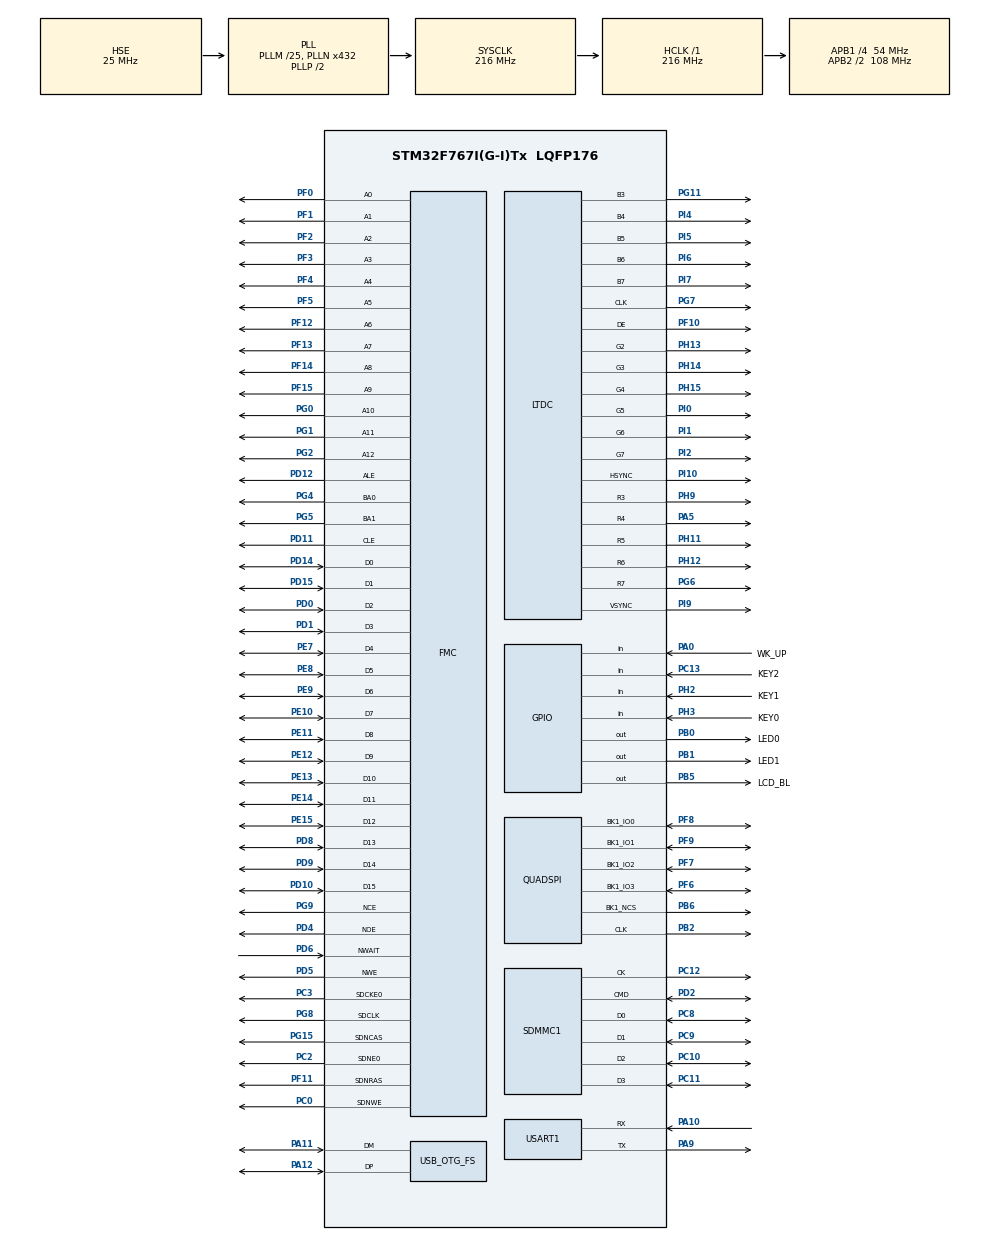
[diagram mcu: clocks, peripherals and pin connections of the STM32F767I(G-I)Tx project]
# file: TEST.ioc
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CORTEX_M7.ART_ACCLERATOR_ENABLE=1
CORTEX_M7.CPU_DCache=Enabled
CORTEX_M7.CPU_ICache=Enabled
CORTEX_M7.PREFETCH_ENABLE=1
Dma.Request0=USART1_RX
Dma.Request1=USART1_TX
Dma.USART1_RX.0.Direction=DMA_PERIPH_TO_MEMORY
Dma.USART1_RX.0.FIFOMode=DMA_FIFOMODE_DISABLE
Dma.USART1_RX.0.Instance=DMA2_Stream2
Dma.USART1_RX.0.MemDataAlignment=DMA_MDATAALIGN_BYTE
Dma.USART1_RX.0.MemInc=DMA_MINC_ENABLE
Dma.USART1_RX.0.Mode=DMA_NORMAL
Dma.USART1_RX.0.PeriphDataAlignment=DMA_PDATAALIGN_BYTE
Dma.USART1_RX.0.PeriphInc=DMA_PINC_DISABLE
Dma.USART1_RX.0.Priority=DMA_PRIORITY_LOW
Dma.USART1_TX.1.Direction=DMA_MEMORY_TO_PERIPH
Dma.USART1_TX.1.FIFOMode=DMA_FIFOMODE_DISABLE
Dma.USART1_TX.1.Instance=DMA2_Stream7
Dma.USART1_TX.1.MemDataAlignment=DMA_MDATAALIGN_BYTE
Dma.USART1_TX.1.MemInc=DMA_MINC_ENABLE
Dma.USART1_TX.1.Mode=DMA_NORMAL
Dma.USART1_TX.1.PeriphDataAlignment=DMA_PDATAALIGN_BYTE
Dma.USART1_TX.1.PeriphInc=DMA_PINC_DISABLE
Dma.USART1_TX.1.Priority=DMA_PRIORITY_LOW
FMC.AttributeSpaceHiZSetupTime1=2
FMC.AttributeSpaceHoldSetupTime1=3
FMC.AttributeSpaceSetupTime1=2
FMC.AttributeSpaceWaitSetupTime1=3
FMC.CASLatency1=FMC_SDRAM_CAS_LATENCY_3
FMC.ColumnBitsNumber1=FMC_SDRAM_COLUMN_BITS_NUM_9
FMC.CommonSpaceHiZSetupTime1=2
FMC.CommonSpaceHoldSetupTime1=3
FMC.CommonSpaceSetupTime1=2
FMC.CommonSpaceWaitSetupTime1=3
FMC.ECCPageSize1=FMC_NAND_ECC_PAGE_SIZE_512BYTE
FMC.EccComputation1=FMC_NAND_ECC_DISABLE
FMC.ExitSelfRefreshDelay1=8
FMC.LoadToActiveDelay1=2
FMC.NandBlockNbr1=4096
FMC.NandBlockSize1=64
FMC.NandPageSize1=2046
FMC.NandPlaneNbr1=2
FMC.NandPlaneSize1=2048
FMC.NandSpareAreaSize1=64
FMC.RCDDelay1=2
FMC.RPDelay1=2
FMC.ReadBurst1=FMC_SDRAM_RBURST_ENABLE
FMC.ReadPipeDelay1=FMC_SDRAM_RPIPE_DELAY_1
FMC.RowCycleDelay1=6
FMC.SDClockPeriod1=FMC_SDRAM_CLOCK_PERIOD_2
FMC.SelfRefreshTime1=6
FMC.WriteRecoveryTime1=4
LTDC.ActiveH=272
LTDC.ActiveW=480
LTDC.Alpha_L0=0xff
LTDC.Alpha_L1=0x7f
LTDC.BlendingFactor1_L0=LTDC_BLENDING_FACTOR1_CA
LTDC.BlendingFactor1_L1=LTDC_BLENDING_FACTOR1_PAxCA
LTDC.BlendingFactor2_L0=LTDC_BLENDING_FACTOR2_CA
LTDC.BlendingFactor2_L1=LTDC_BLENDING_FACTOR2_PAxCA
LTDC.FBStartAdress_L0=0xC0000000  
LTDC.FBStartAdress_L1=0xc00fa000
LTDC.HBP=40
LTDC.HFP=5
LTDC.HSync=1
LTDC.ImageHeight_L0=272
LTDC.ImageHeight_L1=272
LTDC.ImageWidth_L0=480
LTDC.ImageWidth_L1=480
LTDC.Layers=0
LTDC.PixelFormat_L0=LTDC_PIXEL_FORMAT_RGB565
LTDC.PixelFormat_L1=LTDC_PIXEL_FORMAT_RGB565
LTDC.VBP=8
LTDC.VFP=8
LTDC.VSync=1
LTDC.WindowX1_L0=480
LTDC.WindowX1_L1=480
LTDC.WindowY1_L0=272
LTDC.WindowY1_L1=272
Mcu.Family=STM32F7
Mcu.Name=STM32F767I(G-I)Tx
Mcu.Package=LQFP176
NVIC.DMA2_Stream2_IRQn=true\:0\:0\:true\:false\:true\:false\:true
NVIC.DMA2_Stream7_IRQn=true\:0\:0\:false\:false\:true\:false\:true
NVIC.OTG_FS_IRQn=true\:3\:0\:true\:false\:true\:true\:true
NVIC.PriorityGroup=NVIC_PRIORITYGROUP_4
NVIC.TIM3_IRQn=true\:0\:0\:false\:false\:true\:true\:true
NVIC.USART1_IRQn=true\:0\:0\:false\:false\:true\:true\:true
PA0/WKUP.GPIO_Label=WK_UP
PA0/WKUP.GPIO_PuPd=GPIO_PULLDOWN
PA0/WKUP.Signal=GPIO_Input
PA10.Mode=Asynchronous
PA10.Signal=USART1_RX
PA11.Mode=Device_Only
PA11.Signal=USB_OTG_FS_DM
PA12.Mode=Device_Only
PA12.Signal=USB_OTG_FS_DP
PA13.Mode=Serial_Wire
PA13.Signal=SYS_JTMS-SWDIO
PA14.Mode=Serial_Wire
PA14.Signal=SYS_JTCK-SWCLK
PA5.GPIO_Speed=GPIO_SPEED_FREQ_VERY_HIGH
PA5.Mode=RGB565
PA5.Signal=LTDC_R4
PA9.Mode=Asynchronous
PA9.Signal=USART1_TX
PB0.GPIO_Label=LED0
PB0.GPIO_Speed=GPIO_SPEED_FREQ_VERY_HIGH
PB0.Signal=GPIO_Output
PB1.GPIO_Label=LED1
PB1.Signal=GPIO_Output
PB2.Mode=Single Bank 1
PB2.Signal=QUADSPI_CLK
PB5.GPIO_Label=LCD_BL
PB5.GPIO_PuPd=GPIO_PULLUP
PB5.GPIO_Speed=GPIO_SPEED_FREQ_VERY_HIGH
PB5.PinState=GPIO_PIN_SET
PB5.Signal=GPIO_Output
PB6.Mode=Single Bank 1
PB6.Signal=QUADSPI_BK1_NCS
PC0.Signal=FMC_SDNWE
PC10.GPIO_PuPd=GPIO_PULLUP
PC10.Mode=SD_4_bits_Wide_bus
PC10.Signal=SDMMC1_D2
PC11.GPIO_PuPd=GPIO_PULLUP
PC11.Mode=SD_4_bits_Wide_bus
PC11.Signal=SDMMC1_D3
PC12.GPIO_PuPd=GPIO_PULLUP
PC12.Mode=SD_4_bits_Wide_bus
PC12.Signal=SDMMC1_CK
PC13.GPIO_Label=KEY2
PC13.GPIO_PuPd=GPIO_PULLUP
PC13.Signal=GPIO_Input
PC2.Mode=SdramChipSelect1_1
PC2.Signal=FMC_SDNE0
PC3.Mode=SdramChipSelect1_1
PC3.Signal=FMC_SDCKE0
PC8.GPIO_PuPd=GPIO_PULLUP
PC8.Mode=SD_4_bits_Wide_bus
PC8.Signal=SDMMC1_D0
PC9.GPIO_PuPd=GPIO_PULLUP
PC9.Mode=SD_4_bits_Wide_bus
PC9.Signal=SDMMC1_D1
PD0.Signal=FMC_D2_DA2
PD1.Signal=FMC_D3_DA3
PD10.Signal=FMC_D15_DA15
PD11.Signal=FMC_A16_CLE
PD12.Signal=FMC_A17_ALE
PD14.Signal=FMC_D0_DA0
PD15.Signal=FMC_D1_DA1
PD2.GPIO_PuPd=GPIO_PULLUP
PD2.Mode=SD_4_bits_Wide_bus
PD2.Signal=SDMMC1_CMD
PD4.Signal=FMC_NOE
PD5.Signal=FMC_NWE
PD6.Signal=FMC_NWAIT
PD8.Signal=FMC_D13_DA13
PD9.Signal=FMC_D14_DA14
PE10.Signal=FMC_D7_DA7
PE11.Signal=FMC_D8_DA8
PE12.Signal=FMC_D9_DA9
PE13.Signal=FMC_D10_DA10
PE14.Signal=FMC_D11_DA11
PE15.Signal=FMC_D12_DA12
PE7.Signal=FMC_D4_DA4
PE8.Signal=FMC_D5_DA5
PE9.Signal=FMC_D6_DA6
PF0.Signal=FMC_A0
PF1.Signal=FMC_A1
PF10.GPIO_Speed=GPIO_SPEED_FREQ_VERY_HIGH
PF10.Mode=RGB565
PF10.Signal=LTDC_DE
PF11.Signal=FMC_SDNRAS
PF12.Signal=FMC_A6
PF13.Signal=FMC_A7
PF14.Signal=FMC_A8
PF15.Signal=FMC_A9
PF2.Signal=FMC_A2
PF3.Signal=FMC_A3
PF4.Signal=FMC_A4
PF5.Signal=FMC_A5
PF6.Mode=Single Bank 1
PF6.Signal=QUADSPI_BK1_IO3
PF7.Mode=Single Bank 1
PF7.Signal=QUADSPI_BK1_IO2
PF8.Mode=Single Bank 1
PF8.Signal=QUADSPI_BK1_IO0
PF9.Mode=Single Bank 1
PF9.Signal=QUADSPI_BK1_IO1
PG0.Signal=FMC_A10
PG1.Signal=FMC_A11
PG11.GPIO_Speed=GPIO_SPEED_FREQ_VERY_HIGH
PG11.Mode=RGB565
PG11.Signal=LTDC_B3
PG15.Signal=FMC_SDNCAS
PG2.Signal=FMC_A12
PG4.Signal=FMC_A14_BA0
PG5.Signal=FMC_A15_BA1
PG6.GPIO_Speed=GPIO_SPEED_FREQ_VERY_HIGH
PG6.Mode=RGB565
PG6.Signal=LTDC_R7
PG7.GPIO_Speed=GPIO_SPEED_FREQ_VERY_HIGH
PG7.Mode=RGB565
PG7.Signal=LTDC_CLK
PG8.Signal=FMC_SDCLK
PG9.Mode=NandChipSelect3_1
PG9.Signal=FMC_NCE
PH0/OSC_IN.Mode=HSE-External-Oscillator
PH0/OSC_IN.Signal=RCC_OSC_IN
PH1/OSC_OUT.Mode=HSE-External-Oscillator
PH1/OSC_OUT.Signal=RCC_OSC_OUT
PH11.GPIO_Speed=GPIO_SPEED_FREQ_VERY_HIGH
PH11.Mode=RGB565
PH11.Signal=LTDC_R5
PH12.GPIO_Speed=GPIO_SPEED_FREQ_VERY_HIGH
PH12.Mode=RGB565
PH12.Signal=LTDC_R6
PH13.GPIO_Speed=GPIO_SPEED_FREQ_VERY_HIGH
PH13.Mode=RGB565
PH13.Signal=LTDC_G2
PH14.GPIO_Speed=GPIO_SPEED_FREQ_VERY_HIGH
PH14.Mode=RGB565
PH14.Signal=LTDC_G3
PH15.GPIO_Speed=GPIO_SPEED_FREQ_VERY_HIGH
PH15.Mode=RGB565
PH15.Signal=LTDC_G4
PH2.GPIO_Label=KEY1
PH2.GPIO_PuPd=GPIO_PULLUP
PH2.Signal=GPIO_Input
PH3.GPIO_Label=KEY0
PH3.GPIO_PuPd=GPIO_PULLUP
PH3.Signal=GPIO_Input
PH9.GPIO_Speed=GPIO_SPEED_FREQ_VERY_HIGH
PH9.Mode=RGB565
PH9.Signal=LTDC_R3
PI0.GPIO_Speed=GPIO_SPEED_FREQ_VERY_HIGH
PI0.Mode=RGB565
PI0.Signal=LTDC_G5
PI1.GPIO_Speed=GPIO_SPEED_FREQ_VERY_HIGH
PI1.Mode=RGB565
PI1.Signal=LTDC_G6
PI10.GPIO_Speed=GPIO_SPEED_FREQ_VERY_HIGH
PI10.Mode=RGB565
PI10.Signal=LTDC_HSYNC
PI2.GPIO_Speed=GPIO_SPEED_FREQ_VERY_HIGH
PI2.Mode=RGB565
PI2.Signal=LTDC_G7
PI4.GPIO_Speed=GPIO_SPEED_FREQ_VERY_HIGH
PI4.Mode=RGB565
PI4.Signal=LTDC_B4
PI5.GPIO_Speed=GPIO_SPEED_FREQ_VERY_HIGH
PI5.Mode=RGB565
PI5.Signal=LTDC_B5
PI6.GPIO_Speed=GPIO_SPEED_FREQ_VERY_HIGH
PI6.Mode=RGB565
PI6.Signal=LTDC_B6
PI7.GPIO_Speed=GPIO_SPEED_FREQ_VERY_HIGH
PI7.Mode=RGB565
PI7.Signal=LTDC_B7
PI9.GPIO_Speed=GPIO_SPEED_FREQ_VERY_HIGH
PI9.Mode=RGB565
PI9.Signal=LTDC_VSYNC
ProjectManager.HeapSize=0x200
ProjectManager.StackSize=0x800
ProjectManager.TargetToolchain=MDK-ARM V5
QUADSPI.ChipSelectHighTime=QSPI_CS_HIGH_TIME_4_CYCLE
QUADSPI.ClockPrescaler=2
QUADSPI.FifoThreshold=4
QUADSPI.FlashSize=24
QUADSPI.SampleShifting=QSPI_SAMPLE_SHIFTING_HALFCYCLE
RCC.AHBFreq_Value=216000000
RCC.APB1CLKDivider=RCC_HCLK_DIV4
RCC.APB1Freq_Value=54000000
RCC.APB1TimFreq_Value=108000000
RCC.APB2CLKDivider=RCC_HCLK_DIV2
RCC.APB2Freq_Value=108000000
RCC.APB2TimFreq_Value=216000000
RCC.CortexFreq_Value=216000000
RCC.HCLKFreq_Value=216000000
RCC.HSE_VALUE=25000000
RCC.HSI_VALUE=16000000
RCC.LSE_VALUE=32768
RCC.PLLM=25
RCC.PLLN=432
RCC.PLLQ=9
RCC.PLLSAIN=432
RCC.PLLSAIR=6
RCC.PLLSAIRDiv=RCC_PLLSAIDIVR_8
RCC.SDMMCClockSelection=RCC_SDMMC1CLKSOURCE_CLK48
RCC.SYSCLKFreq_VALUE=216000000
RCC.SYSCLKSource=RCC_SYSCLKSOURCE_PLLCLK
RCC.USBFreq_Value=48000000
RCC.VCOOutputFreq_Value=432000000
SH.FMC_A0.0=FMC_A0,13b-sda1
SH.FMC_A1.0=FMC_A1,13b-sda1
SH.FMC_A10.0=FMC_A10,13b-sda1
SH.FMC_A11.0=FMC_A11,13b-sda1
SH.FMC_A12.0=FMC_A12,13b-sda1
SH.FMC_A14_BA0.0=FMC_BA0,FourSdramBanks1
SH.FMC_A15_BA1.0=FMC_BA1,FourSdramBanks1
SH.FMC_A16_CLE.0=FMC_CLE,8b-dmux1
SH.FMC_A17_ALE.0=FMC_ALE,8b-dmux1
SH.FMC_A2.0=FMC_A2,13b-sda1
SH.FMC_A3.0=FMC_A3,13b-sda1
SH.FMC_A4.0=FMC_A4,13b-sda1
SH.FMC_A5.0=FMC_A5,13b-sda1
SH.FMC_A6.0=FMC_A6,13b-sda1
SH.FMC_A7.0=FMC_A7,13b-sda1
SH.FMC_A8.0=FMC_A8,13b-sda1
SH.FMC_A9.0=FMC_A9,13b-sda1
SH.FMC_D0_DA0.0=FMC_D0,sd-16b-d1
SH.FMC_D0_DA0.1=FMC_D0,8b-dmux1
SH.FMC_D10_DA10.0=FMC_D10,sd-16b-d1
SH.FMC_D11_DA11.0=FMC_D11,sd-16b-d1
SH.FMC_D12_DA12.0=FMC_D12,sd-16b-d1
SH.FMC_D13_DA13.0=FMC_D13,sd-16b-d1
SH.FMC_D14_DA14.0=FMC_D14,sd-16b-d1
SH.FMC_D15_DA15.0=FMC_D15,sd-16b-d1
SH.FMC_D1_DA1.0=FMC_D1,sd-16b-d1
SH.FMC_D1_DA1.1=FMC_D1,8b-dmux1
SH.FMC_D2_DA2.0=FMC_D2,sd-16b-d1
SH.FMC_D2_DA2.1=FMC_D2,8b-dmux1
SH.FMC_D3_DA3.0=FMC_D3,sd-16b-d1
SH.FMC_D3_DA3.1=FMC_D3,8b-dmux1
SH.FMC_D4_DA4.0=FMC_D4,sd-16b-d1
SH.FMC_D4_DA4.1=FMC_D4,8b-dmux1
SH.FMC_D5_DA5.0=FMC_D5,sd-16b-d1
SH.FMC_D5_DA5.1=FMC_D5,8b-dmux1
SH.FMC_D6_DA6.0=FMC_D6,sd-16b-d1
SH.FMC_D6_DA6.1=FMC_D6,8b-dmux1
SH.FMC_D7_DA7.0=FMC_D7,sd-16b-d1
SH.FMC_D7_DA7.1=FMC_D7,8b-dmux1
SH.FMC_D8_DA8.0=FMC_D8,sd-16b-d1
SH.FMC_D9_DA9.0=FMC_D9,sd-16b-d1
SH.FMC_NOE.0=FMC_NOE,8b-dmux1
SH.FMC_NWAIT.0=FMC_NWAIT,Wait1
SH.FMC_NWE.0=FMC_NWE,8b-dmux1
SH.FMC_SDCLK.0=FMC_SDCLK,13b-sda1
SH.FMC_SDNCAS.0=FMC_SDNCAS,13b-sda1
SH.FMC_SDNRAS.0=FMC_SDNRAS,13b-sda1
SH.FMC_SDNWE.0=FMC_SDNWE,13b-sda1
TIM3.Period=5000-1
TIM3.Prescaler=10800-1
USART1.VirtualMode-Asynchronous=VM_ASYNC
USB_DEVICE.CLASS_NAME_FS=MSC
USB_DEVICE.USBD_MAX_NUM_INTERFACES-MSC_FS=1
USB_DEVICE.VirtualMode-MSC_FS=Msc
USB_DEVICE.VirtualModeFS=Msc_FS
USB_OTG_FS.VirtualMode=Device_Only
VP_TIM3_VS_ClockSourceINT.Mode=Internal
VP_USB_DEVICE_VS_USB_DEVICE_MSC_FS.Mode=MSC_FS
board=custom

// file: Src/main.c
/* USER CODE BEGIN Header */
/**
  ******************************************************************************
  * @file           : main.c
  * @brief          : Main program body
  ******************************************************************************
  * @attention
  *
  * <h2><center>&copy; Copyright (c) 2019 STMicroelectronics.
  * All rights reserved.</center></h2>
  *
  * This software component is licensed by ST under BSD 3-Clause license,
  * the "License"; You may not use this file except in compliance with the
  * License. You may obtain a copy of the License at:
  *                        opensource.org/licenses/BSD-3-Clause
  *
  ******************************************************************************
  */
/* USER CODE END Header */

#include "main.h"
#include "dma.h"
#include "ltdc.h"
#include "quadspi.h"
#include "sdmmc.h"
#include "tim.h"
#include "usart.h"
#include "usb_device.h"
#include "gpio.h"
#include "fmc.h"

/* USER CODE BEGIN PV */
//uint16_t testsram[250000] __attribute__((at(0XC0000000)));//测试用数组
/* USER CODE END PV */

void SystemClock_Config(void);

int main(void)
{
  /* USER CODE BEGIN 1 */
	FIL fil;
	FATFS fs;
	uint8_t res;
	uint8_t write[19]="this is write test";
	uint8_t read[19];
	UINT wr_bw;
	UINT r_bw;
	uint8_t *buf;
	uint32_t sd_size;
  /* USER CODE END 1 */

  /* Enable I-Cache---------------------------------------------------------*/
  SCB_EnableICache();

  /* Enable D-Cache---------------------------------------------------------*/
  SCB_EnableDCache();

  /* MCU Configuration--------------------------------------------------------*/

  /* Reset of all peripherals, Initializes the Flash interface and the Systick. */
  HAL_Init();

  /* Configure the system clock */
  SystemClock_Config();

  /* Initialize all configured peripherals */
  MX_GPIO_Init();
  MX_DMA_Init();
  MX_USART1_UART_Init();
  MX_TIM3_Init();
  MX_FMC_Init();
  MX_LTDC_Init();
  MX_QUADSPI_Init();
  MX_SDMMC1_SD_Init();
  MX_USB_DEVICE_Init();
  /* USER CODE BEGIN 2 */
  read_sdinfo();//获取SD卡信息
    SDRAM_Init();
//	MPU_Memory_Protection();//MPU内存保护配置
	W25QXX_Init();
    LTDC_LCD_Init();
	my_mem_init(SRAMIN);		    //初始化内部内存池
	my_mem_init(SRAMEX);		    //初始化外部内存池
	my_mem_init(SRAMDTCM);		    //初始化DTCM内存池
	HAL_UART_Receive_IT(&huart1,aRecBuff,1);
    HAL_TIM_Base_Start_IT(&htim3);
	LTDC_ShowString(100,0,32,"F7 TEST");

//	res=f_mount(&fs,"0:",1);

	if(res)
	{
		printf("mount error %d\r\n",res);
	}
	else
	{
		printf("mount success\r\n");
	}
  /* USER CODE END 2 */

  /* Infinite loop */
  while (1)
  {

    /* USER CODE BEGIN 3 */
	  switch(Key_Scan(0))
      {
          case KEY0_PRES:

			  res=f_open(&fil,"0:tttt.txt",FA_CREATE_ALWAYS|FA_WRITE);
				if(res)
				{
					printf("open error %d\r\n",res);
				}
				else
				{
					printf("open success\r\n");
				}
              printf("key0 is press\r\n");
          break;
          case KEY1_PRES:
			   res=f_write(&fil,write,19,&wr_bw);
				if(res)
				{
					printf("write error %d\r\n",res);
				}
				else
				{
					printf("write success\r\n");
				}
              printf("key1 is press\r\n");
          break;
          case KEY2_PRES:
			  res=f_close(&fil);
				if(res)
				{
					printf("close error %d\r\n",res);
				}
				else
				{
					printf("close success\r\n");
				}
              printf("key2 is press\r\n");
          break;
          case WKUP_PRES:
			  res=f_read(&fil,read,19,&r_bw);
				if(res)
				{
					printf("read error %d\r\n",res);
					LTDC_ShowString(0,32,32,"error\r\n");
				}
				else
				{
					printf("read success,size=%d\r\n",r_bw);
					LTDC_ShowString(0,32,32,read);

				}

              printf("wk_up is press\r\n");
          break;
          default : break;
      }
//	  Get_KeyVul();
      HAL_Delay(50);
  }
  /* USER CODE END 3 */
}

void SystemClock_Config(void)
{
  RCC_OscInitTypeDef RCC_OscInitStruct = {0};
  RCC_ClkInitTypeDef RCC_ClkInitStruct = {0};
  RCC_PeriphCLKInitTypeDef PeriphClkInitStruct = {0};

  /** Configure the main internal regulator output voltage
  */
  __HAL_RCC_PWR_CLK_ENABLE();
  __HAL_PWR_VOLTAGESCALING_CONFIG(PWR_REGULATOR_VOLTAGE_SCALE1);
  /** Initializes the CPU, AHB and APB busses clocks
  */
  RCC_OscInitStruct.OscillatorType = RCC_OSCILLATORTYPE_HSE;
  RCC_OscInitStruct.HSEState = RCC_HSE_ON;
  RCC_OscInitStruct.PLL.PLLState = RCC_PLL_ON;
  RCC_OscInitStruct.PLL.PLLSource = RCC_PLLSOURCE_HSE;
  RCC_OscInitStruct.PLL.PLLM = 25;
  RCC_OscInitStruct.PLL.PLLN = 432;
  RCC_OscInitStruct.PLL.PLLP = RCC_PLLP_DIV2;
  RCC_OscInitStruct.PLL.PLLQ = 9;
  if (HAL_RCC_OscConfig(&RCC_OscInitStruct) != HAL_OK)
  {
    Error_Handler();
  }
  /** Activate the Over-Drive mode
  */
  if (HAL_PWREx_EnableOverDrive() != HAL_OK)
  {
    Error_Handler();
  }
  /** Initializes the CPU, AHB and APB busses clocks
  */
  RCC_ClkInitStruct.ClockType = RCC_CLOCKTYPE_HCLK|RCC_CLOCKTYPE_SYSCLK
                              |RCC_CLOCKTYPE_PCLK1|RCC_CLOCKTYPE_PCLK2;
  RCC_ClkInitStruct.SYSCLKSource = RCC_SYSCLKSOURCE_PLLCLK;
  RCC_ClkInitStruct.AHBCLKDivider = RCC_SYSCLK_DIV1;
  RCC_ClkInitStruct.APB1CLKDivider = RCC_HCLK_DIV4;
  RCC_ClkInitStruct.APB2CLKDivider = RCC_HCLK_DIV2;

  if (HAL_RCC_ClockConfig(&RCC_ClkInitStruct, FLASH_LATENCY_7) != HAL_OK)
  {
    Error_Handler();
  }
  PeriphClkInitStruct.PeriphClockSelection = RCC_PERIPHCLK_LTDC|RCC_PERIPHCLK_USART1
                              |RCC_PERIPHCLK_SDMMC1|RCC_PERIPHCLK_CLK48;
  PeriphClkInitStruct.PLLSAI.PLLSAIN = 432;
  PeriphClkInitStruct.PLLSAI.PLLSAIR = 6;
  PeriphClkInitStruct.PLLSAI.PLLSAIQ = 2;
  PeriphClkInitStruct.PLLSAI.PLLSAIP = RCC_PLLSAIP_DIV2;
  PeriphClkInitStruct.PLLSAIDivQ = 1;
  PeriphClkInitStruct.PLLSAIDivR = RCC_PLLSAIDIVR_8;
  PeriphClkInitStruct.Usart1ClockSelection = RCC_USART1CLKSOURCE_PCLK2;
  PeriphClkInitStruct.Clk48ClockSelection = RCC_CLK48SOURCE_PLL;
  PeriphClkInitStruct.Sdmmc1ClockSelection = RCC_SDMMC1CLKSOURCE_CLK48;
  if (HAL_RCCEx_PeriphCLKConfig(&PeriphClkInitStruct) != HAL_OK)
  {
    Error_Handler();
  }
}

void Error_Handler(void)
{
}

/************************ (C) COPYRIGHT STMicroelectronics *****END OF FILE****/
